AUTOSAR XML (schema 4-0-3)
standard types defined: Boolean, UInt16, UInt8
package /AUTOSAR_Platform/DataConstrs
  range DC_Boolean: raw 0..1
  range DC_UInt16: raw 0..65535
package /PATAC/MSM/ComponentTypes
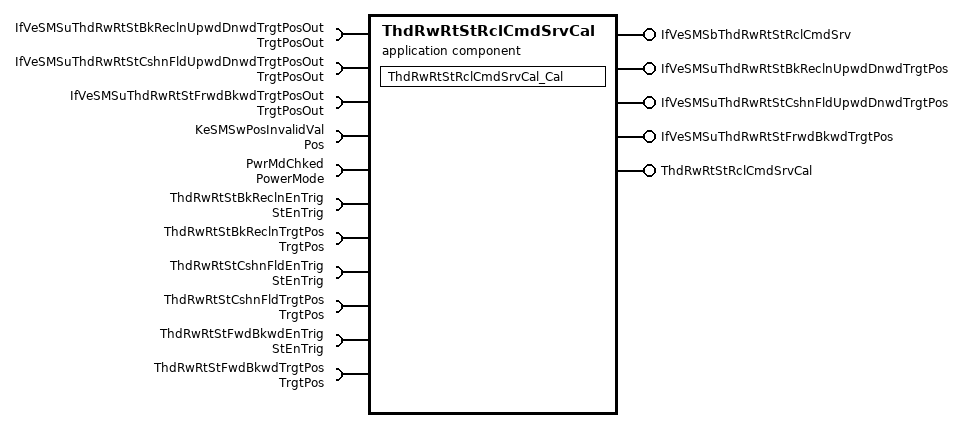
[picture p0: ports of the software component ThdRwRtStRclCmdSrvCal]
  application sw component type ThdRwRtStRclCmdSrvCal
    5 x provide port:
      IfVeSMSbThdRwRtStRclCmdSrv: nonqueued-sender-com-spec=data-element=IfVeSMSbThdRwRtStRclCmdSrv/Val, provided-interface=IfVeSMSbThdRwRtStRclCmdSrv
      IfVeSMSuThdRwRtStBkReclnUpwdDnwdTrgtPos: nonqueued-sender-com-spec{data-element=IfVeSMSuThdRwRtStBkReclnUpwdDnwdTrgtPos/Val, init-value=4095}, provided-interface=IfVeSMSuThdRwRtStBkReclnUpwdDnwdTrgtPos
      IfVeSMSuThdRwRtStCshnFldUpwdDnwdTrgtPos: nonqueued-sender-com-spec{data-element=IfVeSMSuThdRwRtStCshnFldUpwdDnwdTrgtPos/Val, init-value=4095}, provided-interface=IfVeSMSuThdRwRtStCshnFldUpwdDnwdTrgtPos
      IfVeSMSuThdRwRtStFrwdBkwdTrgtPos: nonqueued-sender-com-spec{data-element=IfVeSMSuThdRwRtStFrwdBkwdTrgtPos/Val, init-value=4095}, provided-interface=IfVeSMSuThdRwRtStFrwdBkwdTrgtPos
      ThdRwRtStRclCmdSrvCal: server-com-spec{operation=Cal, queue-length=1}, provided-interface=ThdRwRtStRclCmdSrvCal
    11 x require port:
      IfVeSMSuThdRwRtStBkReclnUpwdDnwdTrgtPosOut: nonqueued-receiver-com-spec{data-element=TrgtPosOut/Val, filter=data-filter-type=ALWAYS, init-value=0}, required-interface=TrgtPosOut
      IfVeSMSuThdRwRtStCshnFldUpwdDnwdTrgtPosOut: nonqueued-receiver-com-spec{data-element=TrgtPosOut/Val, filter=data-filter-type=ALWAYS, init-value=0}, required-interface=TrgtPosOut
      IfVeSMSuThdRwRtStFrwdBkwdTrgtPosOut: nonqueued-receiver-com-spec{data-element=TrgtPosOut/Val, filter=data-filter-type=ALWAYS, init-value=0}, required-interface=TrgtPosOut
      KeSMSwPosInvalidVal: parameter-require-com-spec{init-value=4095, parameter=Val}, required-interface=Pos
      PwrMdChked: nonqueued-receiver-com-spec{data-element=PowerMode/Val, filter=data-filter-type=ALWAYS, init-value=0}, required-interface=PowerMode
      ThdRwRtStBkReclnEnTrig: nonqueued-receiver-com-spec{data-element=StEnTrig/Val, filter=data-filter-type=ALWAYS, init-value=0}, required-interface=StEnTrig
      ThdRwRtStBkReclnTrgtPos: nonqueued-receiver-com-spec{data-element=TrgtPos/Val, filter=data-filter-type=ALWAYS, init-value=4095}, required-interface=TrgtPos
      ThdRwRtStCshnFldEnTrig: nonqueued-receiver-com-spec{data-element=StEnTrig/Val, filter=data-filter-type=ALWAYS, init-value=0}, required-interface=StEnTrig
      ThdRwRtStCshnFldTrgtPos: nonqueued-receiver-com-spec{data-element=TrgtPos/Val, filter=data-filter-type=ALWAYS, init-value=4095}, required-interface=TrgtPos
      ThdRwRtStFwdBkwdEnTrig: nonqueued-receiver-com-spec{data-element=StEnTrig/Val, filter=data-filter-type=ALWAYS, init-value=0}, required-interface=StEnTrig
      ThdRwRtStFwdBkwdTrgtPos: nonqueued-receiver-com-spec{data-element=TrgtPos/Val, filter=data-filter-type=ALWAYS, init-value=4095}, required-interface=TrgtPos
    behavior ThdRwRtStRclCmdSrvCal_InternalBehavior
      operation invoked event OIT_ThdRwRtStRclCmdSrvCal_Cal_ThdRwRtStRclCmdSrvCal_Cal: start-on-event=ThdRwRtStRclCmdSrvCal_Cal, operation=ThdRwRtStRclCmdSrvCal.Cal
      runnable ThdRwRtStRclCmdSrvCal_Cal
        data-receive-point-by-arguments:
          10 x access:
            REC_IfVeSMSuThdRwRtStBkReclnUpwdDnwdTrgtPosOut_Val: accessed-variable=IfVeSMSuThdRwRtStBkReclnUpwdDnwdTrgtPosOut.Val
            REC_IfVeSMSuThdRwRtStCshnFldUpwdDnwdTrgtPosOut_Val: accessed-variable=IfVeSMSuThdRwRtStCshnFldUpwdDnwdTrgtPosOut.Val
            REC_IfVeSMSuThdRwRtStFrwdBkwdTrgtPosOut_Val: accessed-variable=IfVeSMSuThdRwRtStFrwdBkwdTrgtPosOut.Val
            REC_PwrMdChked_Val: accessed-variable=PwrMdChked.Val
            REC_ThdRwRtStBkReclnEnTrig_Val: accessed-variable=ThdRwRtStBkReclnEnTrig.Val
            REC_ThdRwRtStBkReclnTrgtPos_Val: accessed-variable=ThdRwRtStBkReclnTrgtPos.Val
            REC_ThdRwRtStCshnFldEnTrig_Val: accessed-variable=ThdRwRtStCshnFldEnTrig.Val
            REC_ThdRwRtStCshnFldTrgtPos_Val: accessed-variable=ThdRwRtStCshnFldTrgtPos.Val
            REC_ThdRwRtStFwdBkwdEnTrig_Val: accessed-variable=ThdRwRtStFwdBkwdEnTrig.Val
            REC_ThdRwRtStFwdBkwdTrgtPos_Val: accessed-variable=ThdRwRtStFwdBkwdTrgtPos.Val
        data-send-points:
          4 x access:
            SEND_IfVeSMSbThdRwRtStRclCmdSrv_Val: accessed-variable=IfVeSMSbThdRwRtStRclCmdSrv.Val
            SEND_IfVeSMSuThdRwRtStBkReclnUpwdDnwdTrgtPos_Val: accessed-variable=IfVeSMSuThdRwRtStBkReclnUpwdDnwdTrgtPos.Val
            SEND_IfVeSMSuThdRwRtStCshnFldUpwdDnwdTrgtPos_Val: accessed-variable=IfVeSMSuThdRwRtStCshnFldUpwdDnwdTrgtPos.Val
            SEND_IfVeSMSuThdRwRtStFrwdBkwdTrgtPos_Val: accessed-variable=IfVeSMSuThdRwRtStFrwdBkwdTrgtPos.Val
        parameter access PA_KeSMSwPosInvalidVal_Val: accessed-parameter=KeSMSwPosInvalidVal.Val
  swc implementation ThdRwRtStRclCmdSrvCal_Implementation: behavior=ThdRwRtStRclCmdSrvCal_InternalBehavior
    code-descriptors:
      code Default: artifact-descriptors=autosar-engineering-object={short-label=Default, category=SWSRC}
package /PATAC/MSM/ModeAdjust/CalPortInterface
  parameter interface Pos
    parameter data prototype Val: sw-calibration-access=READ-WRITE, type=UInt16
package /PATAC/MSM/ModeAdjust/DataType
  impl type PowerMode1: category=VALUE, base-type=UInt8, sw-calibration-access=READ-ONLY, compu {0=PowerMode_Off, 1=PowerMode_Acc, 2=PowerMode_Run, 3=PowerMode_Crank, 4=PowerMode_Invalid}, type-emitter=RTE
package /PATAC/MSM/ModeAdjust/Interfaces
  sender receiver interface IfVeSMSbThdRwRtStRclCmdSrv: invalidation-policy{data-element=IfVeSMSbThdRwRtStRclCmdSrv/Val, handle-invalid=DONT-INVALIDATE}
    data Val: type=Boolean
  sender receiver interface IfVeSMSuThdRwRtStCshnFldUpwdDnwdTrgtPos: invalidation-policy{data-element=IfVeSMSuThdRwRtStCshnFldUpwdDnwdTrgtPos/Val, handle-invalid=DONT-INVALIDATE}
    data Val: type=UInt16
package /PATAC/MSM/ModeAdjust/PortInterface
  client server interface ThdRwRtStRclCmdSrvCal
    operation Cal
  sender receiver interface PowerMode: invalidation-policy{data-element=PowerMode/Val, handle-invalid=DONT-INVALIDATE}
    data Val: type=PowerMode1
  sender receiver interface StEnTrig: invalidation-policy{data-element=StEnTrig/Val, handle-invalid=DONT-INVALIDATE}
    data Val: type=Boolean
  sender receiver interface TrgtPosOut: invalidation-policy{data-element=TrgtPosOut/Val, handle-invalid=DONT-INVALIDATE}
    data Val: type=Boolean
package /PATAC/MSM/PortInterfaces
  sender receiver interface IfVeSMSuThdRwRtStBkReclnUpwdDnwdTrgtPos: invalidation-policy{data-element=IfVeSMSuThdRwRtStBkReclnUpwdDnwdTrgtPos/Val, handle-invalid=DONT-INVALIDATE}
    data Val: type=UInt16
  sender receiver interface IfVeSMSuThdRwRtStFrwdBkwdTrgtPos: invalidation-policy{data-element=IfVeSMSuThdRwRtStFrwdBkwdTrgtPos/Val, handle-invalid=DONT-INVALIDATE}
    data Val: type=UInt16
  sender receiver interface TrgtPos: invalidation-policy{data-element=TrgtPos/Val, handle-invalid=DONT-INVALIDATE}
    data Val: type=UInt16
